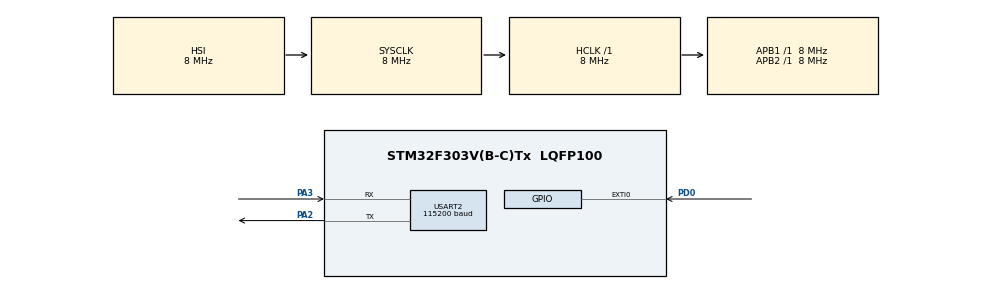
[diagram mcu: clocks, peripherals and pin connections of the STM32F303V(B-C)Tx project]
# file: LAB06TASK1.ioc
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Mcu.Family=STM32F3
Mcu.Name=STM32F303V(B-C)Tx
Mcu.Package=LQFP100
NVIC.EXTI0_IRQn=true\:0\:0\:false\:false\:true\:true\:true\:true
NVIC.PriorityGroup=NVIC_PRIORITYGROUP_4
NVIC.TIM2_IRQn=true\:0\:0\:false\:false\:true\:true\:true\:true
PA2.Mode=Asynchronous
PA2.Signal=USART2_TX
PA3.Mode=Asynchronous
PA3.Signal=USART2_RX
PD0.GPIO_ModeDefaultEXTI=GPIO_MODE_IT_RISING
PD0.Signal=GPXTI0
ProjectManager.HeapSize=0x200
ProjectManager.StackSize=0x400
ProjectManager.TargetToolchain=CMake
RCC.AHBFreq_Value=8000000
RCC.APB1Freq_Value=8000000
RCC.APB2Freq_Value=8000000
RCC.CortexFreq_Value=8000000
RCC.HSE_VALUE=8000000
RCC.HSI_VALUE=8000000
RCC.LSE_VALUE=32768
RCC.SYSCLKFreq_VALUE=8000000
TIM2.AutoReloadPreload=TIM_AUTORELOAD_PRELOAD_DISABLE
TIM2.Period=100000
TIM2.Prescaler=9
USART2.BaudRate=115200
USART2.VirtualMode-Asynchronous=VM_ASYNC
VP_TIM2_VS_ClockSourceINT.Mode=Internal
board=custom

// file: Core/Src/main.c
/* USER CODE BEGIN Header */
/**
  ******************************************************************************
  * @file           : main.c
  * @brief          : Main program body
  ******************************************************************************
  * @attention
  *
  * Copyright (c) 2026 STMicroelectronics.
  * All rights reserved.
  *
  * This software is licensed under terms that can be found in the LICENSE file
  * in the root directory of this software component.
  * If no LICENSE file comes with this software, it is provided AS-IS.
  *
  ******************************************************************************
  */
/* USER CODE END Header */
#include "main.h"
#include "stm32f3xx_hal.h"  // HAL library for STM32
#include <string.h>
#include <stdio.h>

#define SAMPLE_SIZE 10

volatile uint32_t captures[SAMPLE_SIZE];
volatile uint8_t captureIndex = 0;

volatile uint8_t firstEdge = 0;
volatile uint8_t printFlag = 0;

char uart_buffer[100];  //

TIM_HandleTypeDef htim2;

UART_HandleTypeDef huart2;

void SystemClock_Config(void);
static void MX_GPIO_Init(void);
static void MX_TIM2_Init(void);
static void MX_USART2_UART_Init(void);

int main(void)
{

  /* MCU Configuration--------------------------------------------------------*/

  /* Reset of all peripherals, Initializes the Flash interface and the Systick. */
  HAL_Init();

  /* Configure the system clock */
  SystemClock_Config();

  /* Initialize all configured peripherals */
  MX_GPIO_Init();
  MX_TIM2_Init();
  MX_USART2_UART_Init();
  /* USER CODE BEGIN 2 */
  HAL_TIM_Base_Start(&htim2);
  /* USER CODE END 2 */

  /* Infinite loop */
  while (1)
  {

    HAL_Delay(100);  // check every 100 ms

    if(printFlag)
    {
        printFlag = 0;  // reset flag

        uint32_t sum = 0;
        for(uint8_t i = 0; i < SAMPLE_SIZE; i++)
            sum += captures[i];

        uint32_t avg = sum / SAMPLE_SIZE; //avging muliple periods

        // compute frequency: SystemCoreClock = 8 MHz, prescaler = 9 → divide by 10
        uint32_t freq_int = 800000 / avg; //f=timer freq/period(avg)

        sprintf(uart_buffer, "Freq: %lu Hz\r\n", freq_int);
        HAL_UART_Transmit(&huart2, (uint8_t*)uart_buffer, strlen(uart_buffer), HAL_MAX_DELAY);
        printFlag = 0;
    }
  }
}

void SystemClock_Config(void)
{
  RCC_OscInitTypeDef RCC_OscInitStruct = {0};
  RCC_ClkInitTypeDef RCC_ClkInitStruct = {0};
  RCC_PeriphCLKInitTypeDef PeriphClkInit = {0};

  /** Initializes the RCC Oscillators according to the specified parameters
  * in the RCC_OscInitTypeDef structure.
  */
  RCC_OscInitStruct.OscillatorType = RCC_OSCILLATORTYPE_HSI;
  RCC_OscInitStruct.HSIState = RCC_HSI_ON;
  RCC_OscInitStruct.HSICalibrationValue = RCC_HSICALIBRATION_DEFAULT;
  RCC_OscInitStruct.PLL.PLLState = RCC_PLL_NONE;
  if (HAL_RCC_OscConfig(&RCC_OscInitStruct) != HAL_OK)
  {
    Error_Handler();
  }

  /** Initializes the CPU, AHB and APB buses clocks
  */
  RCC_ClkInitStruct.ClockType = RCC_CLOCKTYPE_HCLK|RCC_CLOCKTYPE_SYSCLK
                              |RCC_CLOCKTYPE_PCLK1|RCC_CLOCKTYPE_PCLK2;
  RCC_ClkInitStruct.SYSCLKSource = RCC_SYSCLKSOURCE_HSI;
  RCC_ClkInitStruct.AHBCLKDivider = RCC_SYSCLK_DIV1;
  RCC_ClkInitStruct.APB1CLKDivider = RCC_HCLK_DIV1;
  RCC_ClkInitStruct.APB2CLKDivider = RCC_HCLK_DIV1;

  if (HAL_RCC_ClockConfig(&RCC_ClkInitStruct, FLASH_LATENCY_0) != HAL_OK)
  {
    Error_Handler();
  }
  PeriphClkInit.PeriphClockSelection = RCC_PERIPHCLK_USART2;
  PeriphClkInit.Usart2ClockSelection = RCC_USART2CLKSOURCE_PCLK1;
  if (HAL_RCCEx_PeriphCLKConfig(&PeriphClkInit) != HAL_OK)
  {
    Error_Handler();
  }
}

static void MX_TIM2_Init(void)
{

  TIM_ClockConfigTypeDef sClockSourceConfig = {0};
  TIM_MasterConfigTypeDef sMasterConfig = {0};

  htim2.Instance = TIM2;
  htim2.Init.Prescaler = 9;
  htim2.Init.CounterMode = TIM_COUNTERMODE_UP;
  htim2.Init.Period = 100000;
  htim2.Init.ClockDivision = TIM_CLOCKDIVISION_DIV1;
  htim2.Init.AutoReloadPreload = TIM_AUTORELOAD_PRELOAD_DISABLE;
  if (HAL_TIM_Base_Init(&htim2) != HAL_OK)
  {
    Error_Handler();
  }
  sClockSourceConfig.ClockSource = TIM_CLOCKSOURCE_INTERNAL;
  if (HAL_TIM_ConfigClockSource(&htim2, &sClockSourceConfig) != HAL_OK)
  {
    Error_Handler();
  }
  sMasterConfig.MasterOutputTrigger = TIM_TRGO_RESET;
  sMasterConfig.MasterSlaveMode = TIM_MASTERSLAVEMODE_DISABLE;
  if (HAL_TIMEx_MasterConfigSynchronization(&htim2, &sMasterConfig) != HAL_OK)
  {
    Error_Handler();
  }

}

static void MX_USART2_UART_Init(void)
{

  huart2.Instance = USART2;
  huart2.Init.BaudRate = 115200;
  huart2.Init.WordLength = UART_WORDLENGTH_8B;
  huart2.Init.StopBits = UART_STOPBITS_1;
  huart2.Init.Parity = UART_PARITY_NONE;
  huart2.Init.Mode = UART_MODE_TX_RX;
  huart2.Init.HwFlowCtl = UART_HWCONTROL_NONE;
  huart2.Init.OverSampling = UART_OVERSAMPLING_16;
  huart2.Init.OneBitSampling = UART_ONE_BIT_SAMPLE_DISABLE;
  huart2.AdvancedInit.AdvFeatureInit = UART_ADVFEATURE_NO_INIT;
  if (HAL_UART_Init(&huart2) != HAL_OK)
  {
    Error_Handler();
  }

}

static void MX_GPIO_Init(void)
{
  GPIO_InitTypeDef GPIO_InitStruct = {0};

  /* GPIO Ports Clock Enable */
  __HAL_RCC_GPIOA_CLK_ENABLE();
  __HAL_RCC_GPIOD_CLK_ENABLE();

  /*Configure GPIO pin : PD0 */
  GPIO_InitStruct.Pin = GPIO_PIN_0;
  GPIO_InitStruct.Mode = GPIO_MODE_IT_RISING;
  GPIO_InitStruct.Pull = GPIO_NOPULL;
  HAL_GPIO_Init(GPIOD, &GPIO_InitStruct);

  /* EXTI interrupt init*/
  HAL_NVIC_SetPriority(EXTI0_IRQn, 0, 0);
  HAL_NVIC_EnableIRQ(EXTI0_IRQn);

}

/* USER CODE BEGIN 4 */
void HAL_GPIO_EXTI_Callback(uint16_t GPIO_Pin)
{
    if(GPIO_Pin == GPIO_PIN_0)
    {
        if(firstEdge == 0)
        {
            HAL_TIM_Base_Start(&htim2);   // start the timer
            __HAL_TIM_SET_COUNTER(&htim2, 0);  // reset timer
            firstEdge = 1;
        }
        else
        {
            uint32_t time = __HAL_TIM_GET_COUNTER(&htim2);
            captures[captureIndex++] = time;

            if(captureIndex >= SAMPLE_SIZE)
            {
                captureIndex = 0;
                printFlag = 1;  // signal main loop to print
            }

            firstEdge = 0;
        }
    }
}
/* USER CODE END 4 */

void Error_Handler(void)
{
  __disable_irq();
  while (1)
  {
  }
}
